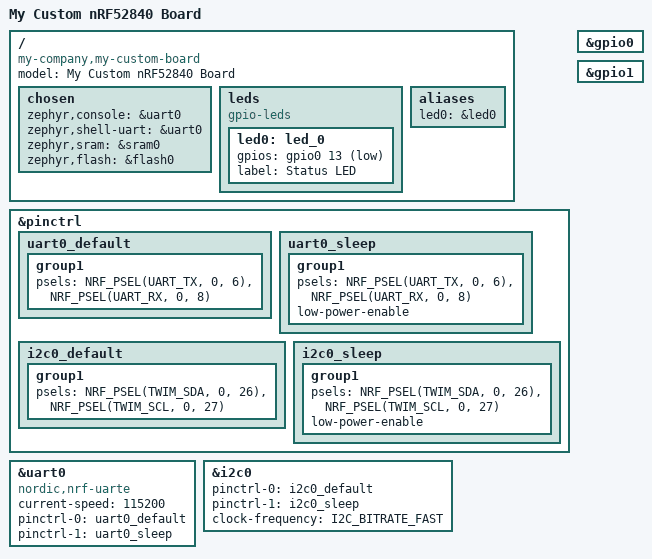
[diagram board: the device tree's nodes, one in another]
/dts-v1/;
#include <nordic/nrf52840_qiaa.dtsi>
#include <zephyr/dt-bindings/gpio/gpio.h>
#include <zephyr/dt-bindings/i2c/i2c.h>

/ {
	model = "My Custom nRF52840 Board";
	compatible = "my-company,my-custom-board";

	chosen {
		zephyr,console = &uart0;
		zephyr,shell-uart = &uart0;
		zephyr,sram = &sram0;
		zephyr,flash = &flash0;
	};

	leds {
		compatible = "gpio-leds";
		led0: led_0 {
			/* Update pin number to match your schematic */
			gpios = <&gpio0 13 GPIO_ACTIVE_LOW>;
			label = "Status LED";
		};
	};

	aliases {
		led0 = &led0;
	};
};

&pinctrl {
	uart0_default: uart0_default {
		group1 {
			/* Update TX/RX pins to match your schematic */
			psels = <NRF_PSEL(UART_TX, 0, 6)>,
				<NRF_PSEL(UART_RX, 0, 8)>;
		};
	};
	uart0_sleep: uart0_sleep {
		group1 {
			psels = <NRF_PSEL(UART_TX, 0, 6)>,
				<NRF_PSEL(UART_RX, 0, 8)>;
			low-power-enable;
		};
	};
	i2c0_default: i2c0_default {
		group1 {
			/* Update SDA/SCL pins to match your schematic */
			psels = <NRF_PSEL(TWIM_SDA, 0, 26)>,
				<NRF_PSEL(TWIM_SCL, 0, 27)>;
		};
	};
	i2c0_sleep: i2c0_sleep {
		group1 {
			psels = <NRF_PSEL(TWIM_SDA, 0, 26)>,
				<NRF_PSEL(TWIM_SCL, 0, 27)>;
			low-power-enable;
		};
	};
};

&uart0 {
	status = "okay";
	compatible = "nordic,nrf-uarte";
	current-speed = <115200>;
	pinctrl-0 = <&uart0_default>;
	pinctrl-1 = <&uart0_sleep>;
	pinctrl-names = "default", "sleep";
};

&i2c0 {
	status = "okay";
	pinctrl-0 = <&i2c0_default>;
	pinctrl-1 = <&i2c0_sleep>;
	pinctrl-names = "default", "sleep";
	clock-frequency = <I2C_BITRATE_FAST>;
};

&gpio0 {
	status = "okay";
};

&gpio1 {
	status = "okay";
};
